# G32R430xx register map
Vendor: Geehy Semiconductor Co., Ltd.; Series: G32R4; File version: 1.0
CPU: CM52 r0p1, little endian, MPU, no FPU, DSP, VTOR, 4 interrupt priority bits
Registers are 32-bit, read-write, reset 0x0 unless marked. A register's access mark holds for its fields unless they carry their own. Offsets are from the block's base; [hi:lo] are bit positions; lines under a group give offsets from that group; {n}, {i} and the like mark numbered series.

## ADC1 — Analog to digital converter(16 bit)
Base 0x40020C00
Same registers: ADC2 0x40021000
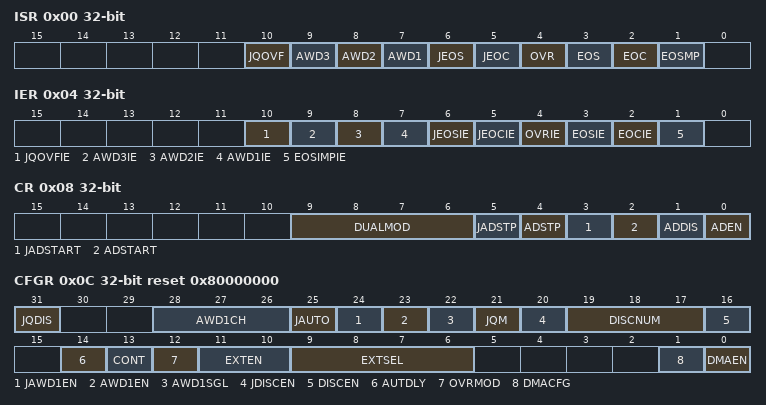
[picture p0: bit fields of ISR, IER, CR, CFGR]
0x00 ISR — ADC interrupt and status register
  [10] JQOVF — Injected context queue overflow
  [9] AWD3 — Analog watchdog 3 flag
  [8] AWD2 — Analog watchdog 2 flag
  [7] AWD1 — Analog watchdog 1 flag
  [6] JEOS — Injected channel end of sequence flag
  [5] JEOC — Injected channel end of conversion flag
  [4] OVR — ADC Overrun
  [3] EOS — End of regular sequence flag
  [2] EOC — End of conversion flag
  [1] EOSMP — End of sampling flag
0x04 IER — ADC interrupt enable register
  [10] JQOVFIE — Injected context queue overflow interrupt enable
  [9] AWD3IE — Analog watchdog 3 interrupt enable
  [8] AWD2IE — Analog watchdog 2 interrupt enable
  [7] AWD1IE — Analog watchdog 1 interrupt enable
  [6] JEOSIE — End of injected sequence of conversions interrupt enable
  [5] JEOCIE — End of injected conversion interrupt enable
  [4] OVRIE — Overrun interrupt enable
  [3] EOSIE — End of regular sequence of conversions interrupt enable
  [2] EOCIE — End of regular conversion interrupt enable
  [1] EOSIMPIE — End of sampling flag interrupt enable for regular conversions
0x08 CR — ADC control register
  [9:6] DUALMOD — DUAL MODE SELECTION
  [5] JADSTP — ADC STOP OF INJECTED CONVERSION COMMAND
  [4] ADSTP — ADC STOP OF REGULAR CONVERSION COMMAND
  [3] JADSTART — ADC START OF INJECTED CONVERSION
  [2] ADSTART — ADC START OF REGULAR CONVERSION
  [1] ADDIS — ADC DISABLE COMMAND
  [0] ADEN — ADC ENABLE CONTROL
0x0C CFGR reset 0x80000000 — ADC configuration register 1
  [31] JQDIS — INJECTED QUEUE DISABLE
  [28:26] AWD1CH — ADC analog watchdog 1 monitored channel selection
  [25] JAUTO — ADC group injected automatic trigger mode
  [24] JAWD1EN — ADC analog watchdog 1 enable on scope ADC group injected
  [23] AWD1EN — ADC analog watchdog 1 enable on scope ADC group regular
  [22] AWD1SGL — ADC analog watchdog 1 monitoring a single channel or all channels
  [21] JQM — JSQR QUEUE MODE
  [20] JDISCEN — ADC group injected sequencer discontinuous mode
  [19:17] DISCNUM — ADC group regular sequencer discontinuous number of ranks
  [16] DISCEN — ADC group regular sequencer discontinuous mode
  [14] AUTDLY — DELAYED CONVERSION MODE
  [13] CONT — ADC group regular continuous conversion mode
  [12] OVRMOD — OVERRUN MODE
  [11:10] EXTEN — ADC group regular external trigger polarity
  [9:6] EXTSEL — ADC group regular external trigger source
  [1] DMACFG — DIRECT MEMORY ACCESS CONFIGURATION
  [0] DMAEN — ADC DMA transfer enable
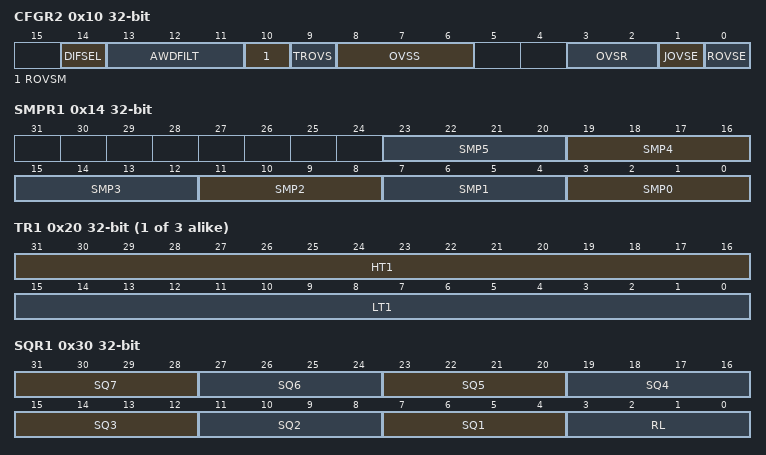
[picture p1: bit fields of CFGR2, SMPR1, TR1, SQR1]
0x10 CFGR2 — ADC configuration register 2
  [14] DIFSEL — ADC Single-End/Differential Mode Control Signal
  [13:11] AWDFILT — ANALOG WATCHDOG FILTERING PARAMETER
  [10] ROVSM — REGULAR OVERSAMPLING MODE
  [9] TROVS — TRIGGERED REGULAR OVERSAMPLING
  [8:6] OVSS — OVERSAMPLING SHIFT
  [3:2] OVSR — OVERSAMPLING RATIO
  [1] JOVSE — INJECTED OVERSAMPLING ENABLE
  [0] ROVSE — REGULAR OVERSAMPLING ENABLE
0x14 SMPR1 — ADC sampling time register 1
  [4n+3:4n] SMP{n} (n=0..5) — ADC channel {n} sampling time selection
{0x1C+4i} TR{i} (i=1..3) — ADC analog watchdog {i} threshold register
  [{35-4i}:16] HT{i} — ADC analog watchdog {i} threshold high
  [{19-4i}:0] LT{i} — ADC analog watchdog {i} threshold low
0x30 SQR1 — ADC group regular sequencer register 1
  [4n+3:4n] SQ{n} (n=1..7) — ADC group regular sequencer rank {n}
  [3:0] RL — ADC group regular sequencer scan length
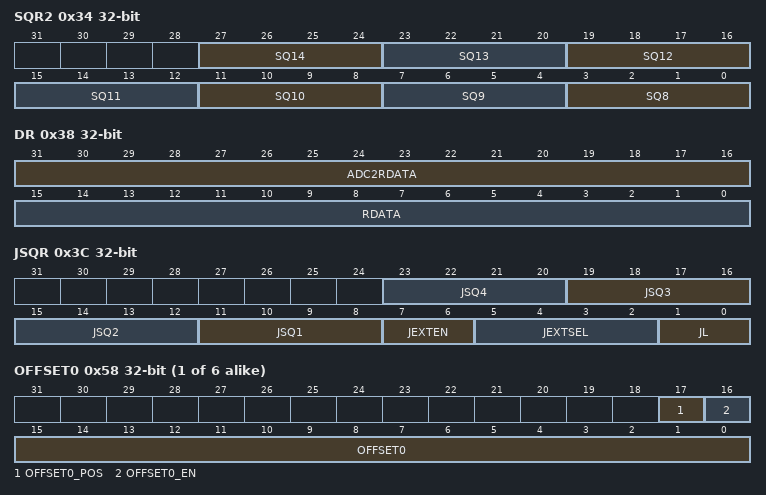
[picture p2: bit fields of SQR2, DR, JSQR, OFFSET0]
0x34 SQR2 — ADC group regular sequencer register 2
  [4n-29:4n-32] SQ{n} (n=8..14) — ADC group regular sequencer rank {n}
0x38 DR ro — ADC group regular data register
  [31:16] ADC2RDATA — The data converted by ADC2 (ADC2 DATA) In dual mode, these bits contain the regular channel data converted by ADC2.
  [15:0] RDATA — ADC group regular conversion data
0x3C JSQR — ADC group injected sequencer register
  [4n+7:4n+4] JSQ{n} (n=1..4) — ADC group injected sequencer rank {n}
  [7:6] JEXTEN — ADC group injected external trigger polarity
  [5:2] JEXTSEL — ADC group injected external trigger source
  [1:0] JL — ADC group injected sequencer scan length
{0x3C+4i} JDR{i} ro (i=1..4) — ADC group injected rank {i} data register
  [15:0] JDATA — ADC group injected sequencer rank {i} conversion data
0x50 AWD2CR — Simulation Watchdog 2 Control Register
  [5:0] AWD2CH — ANALOG WATCHDOG 2 CHANNEL SELECTION
0x54 AWD3CR — Simulation Watchdog 3 Control Register
  [5:0] AWD3CH — ANALOG WATCHDOG 3 CHANNEL SELECTION
{0x58+4i} OFFSET{i} (i=0..5) — ADC offset register {i}
  [17] OFFSET{i}_POS — POSITIVE OFFSET THIS BIT IS SET AND CLEARED BY SOFTWARE TO ENABLE THE POSITIVE OFFSET. 0: NEGATIVE OFFSET 1: POSITIVE OFFSET NOTE: THE SOFTWARE IS ALLOWED TO WRITE THESE BITS ONLY WHEN ADSTART = 0 AND JADSTART = 0 (WHICH ENSURES THAT NO CONVERSION IS ONGOING)
  [16] OFFSET{i}_EN — This bit is enabled and disabled by software writing for programming into the OFFSET{i} bit. Note: Writing to this bit through software is only allowed when ADSTART=0 and JADSTART=0 (this ensures that no conversion is currently taking place).
  [15:0] OFFSET{i} — The data offset compensation corresponding to the channel (single-ended mode INP<0>/differential mode<0>) These bits are written by software, used to define the offset subtracted from the original conversion data when converting the channel (can be regular channel or injection channel) Note: Writing to these bits through software is only allowed when ADSTART=0 and JADSTART=0 (this ensures that no conversion is currently taking place).
0x80 CAL reset 0x2 — ADC Calibration Register
  [3] REF_SEL — ADC REFERENCE Voltage Selection 1.65/AVDD Control Signal
